# ospreyadc_secure register map
Vendor: Texas Instruments
Peripheral module from a debugger description file (folder CC35X1E).
Registers are 32-bit, read-write, reset 0x0 unless marked. A register's access mark holds for its fields unless they carry their own. Offsets are as the file gives them; lines under a group give offsets from that group; [hi:lo] are bit positions; {n}, {i} and the like mark numbered series; 'fields as' and 'values as' point back to an identical list; <NAME> marks a mode.

## ospreyadc_secure
0x00 adc_control0 reset 0x44554A — FUSE CONTROL 0 Primarily for lab testing, needs to be written by TI boot code All may not be used now, few spare are kept intentionally
  [31:0] TRIM0 — TRIM VALUE 0
0x04 adc_control1 reset 0x18F06630 — FUSE CONTROL 1 Primarily for lab testing, needs to be written by TI boot code All may not be used now, few spare are kept intentionally
  [31:0] TRIM1 — TRIM VALUE 1
0x08 adc_control2 reset 0x10208A — FUSE CONTROL 2 Primarily for lab testing, needs to be written by TI boot code All may not be used now, few spare are kept intentionally
  [31:0] TRIM2 — TRIM VALUE 2
0x0C adc_control3 — FUSE CONTROL 3 Primarily for lab testing, needs to be written by TI boot code All may not be used now, few spare are kept intentionally
  [15:0] TRIM3 — TRIM VALUE 3
0x10 refbuf reset 0xA6E09 — REFERENCE BUFFER
  [31:0] CFG — CONFIG bit[0] - Enable Internal Reference Mode bits[3:1] - Vsel for 3.3V mode Internal Reference Mode. Vrefbuf = 1.3V bits[6:4] - Vsel bits for higher tap points - For debug purpose <6:4> --> 001 (0.9V) <6:4> --> 010 (1.45V) <6:4> --> 100 (1.4V) bits[8:7] - Enable Test mux to check ground and reference thought test pins 01--> Vref Internal available to measure 10 --> vss Internal Reference available to measure bits[10:9] - Trim bits to change the bias current in Ref buf 1st stage bits[12:11] - Trim bits to change the bias current in Ref buf bits[14:13] - Trim bits to change the bias current in Ref buf output stage bits[16:15] - NU bits[19:17] - Vsel for 1.8V mode Internal Reference Mode .Vrefbuf = 1.35V bits[31:20] - NU
0x14 atb
  [7:0] CTRL — CONTROL bit0- master enable of test mux for AIP bit1- refbuf test enable bit2- 20uA current (scaled from PMCIO) test enable bit3- vbat_div test enable bit4- Tsense test enable bit5- Bandgap 0p9v test enable bit6- No connect bit7- No connect
0x1020 int_event0_iidx ro — INTERNAL EVENT 0 IRQ IDX This register provides the highest priority enabled interrupt index. 0x0 means no event pending. Interrupt 1 is the highest priority, 2 next highest, 4, 8, ... 2^31 is the least priority. That is, the least bit position that is set to 1 denotes the highest priority pending interrupt. The priority order is fixed. However, users can implement their own prioritization schemes using other registers that expose the full set of interrupts that have occurred. On each read, only one interrupt is indicated. On a read, the current interrupt (highest priority) is automatically cleared by the hardware and the corresponding interrupt flag in the RIS and MIS are cleared as well. After a read from the CPU (not from the debug interface), the register must be updated with the next highest priority interrupt, if none are pending, then it should display 0x0.
  [9:0] STAT — Interrupt index status
    0=NO_INTR (No bit is set means there is no pending interrupt request); 1=OVIFG (MEMRESx overflow interrupt); 7=UVIFG (MEMRESx underflow interrupt); 2=TOVIFG (Sequence Conversion time overflow interrupt); 3=HIGHIFG (High threshold compare interrupt); 4=LOWIFG (Low threshold compare interrupt); 5=INIFG (Primary Sequence In range comparator interrupt); {v}=MEMRESIFG{v-9} (MEMRES{v-9} data loaded interrupt) (v=9..32); 6=DMADONE (DMA done interrupt, generated on DMA transfer completion,)
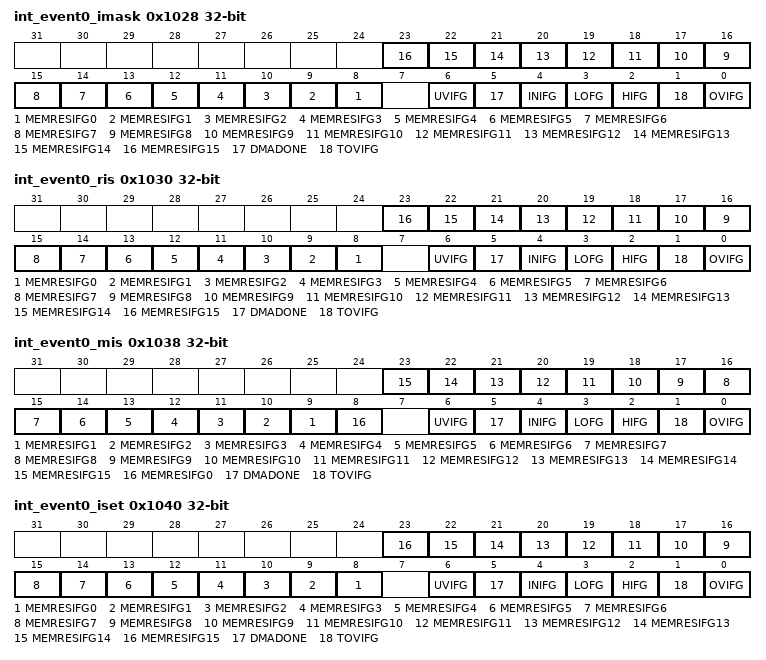
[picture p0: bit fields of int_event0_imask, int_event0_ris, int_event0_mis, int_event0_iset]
0x1028 int_event0_imask — INTERNAL EVENT 0 IRQ MASK Interrupt Mask. If a bit is set, then corresponding interrupt is un-masked. Un-masking the interrupt causes the raw interrupt to be visible in IIDX, as well as MIS.
  [n+8] MEMRESIFG{n} (n=0..15) — Raw interrupt status for MEMRES{n}. This bit is set to 1 when MEMRES{n} is loaded with a new conversion result. To clear this bit, corresponding bit in ICLR should be set to 1
    0=CLR (No new data ready.); 1=SET (A new data is ready to be read.)
  [6] UVIFG — Raw interrupt flag for MEMRESx underflow. This bit is reset to 0 by IIDX read or when corresponding bit in ICLR is set to 1.
    0=CLR (Interrupt is not pending.); 1=SET (Interrupt is pending.)
  [5] DMADONE — Raw interrupt flag for DMADONE. This bit is reset to 0 by IIDX read or when corresponding bit in ICLR_EX is set to 1.
    values as UVIFG
  [4] INIFG — Mask INIFG in MIS_EX register.
    values as UVIFG
  [3] LOFG — LOW FG Raw interrupt flag for the MEMRESx result register being below than the WCLOWx threshold of the window comparator. This bit is reset to 0 by IIDX read or when corresponding bit in ICLR_EX is set to 1.
    values as UVIFG
  [2] HIFG — Raw interrupt flag for the MEMRESx result register being higher than the WCHIGHx threshold of the window comparator. This bit is reset to 0 by IIDX read or when corresponding bit in ICLR_EX is set to 1.
    values as UVIFG
  [1] TOVIFG — Raw interrupt flag for sequence conversion timeout overflow. This bit is reset to 0 by IIDX read or when corresponding bit in ICLR_EX is set to 1.
    values as UVIFG
  [0] OVIFG — Raw interrupt flag for MEMRESx overflow. This bit is reset to 0 by IIDX read or when corresponding bit in ICLR_EX is set to 1.
    values as UVIFG
0x1030 int_event0_ris ro — INTERNAL EVENT 0 RAW IRQ STATUS Raw interrupt status. Reflects all pending interrupts, regardless of masking. The INT_EVENT0_RIS register allows the user to implement a poll scheme. A flag set in this register can be cleared by writing 1 to the ICLR register bit even if the corresponding IMASK bit is not enabled.
  [n+8] MEMRESIFG{n} (n=0..15) — Raw interrupt status for MEMRES{n}. This bit is set to 1 when MEMRES{n} is loaded with a new conversion result. To clear this bit, corresponding bit in ICLR should be set to 1
    values as int_event0_imask.MEMRESIFG0
  [6] UVIFG — Raw interrupt flag for MEMRESx underflow. This bit is reset to 0 by IIDX read or when corresponding bit in ICLR is set to 1.
    values as int_event0_imask.UVIFG
  [5] DMADONE — Raw interrupt flag for DMADONE. This bit is reset to 0 by IIDX read or when corresponding bit in ICLR_EX is set to 1.
    values as int_event0_imask.UVIFG
  [4] INIFG — Mask INIFG in MIS_EX register.
    values as int_event0_imask.UVIFG
  [3] LOFG — LOW FG Raw interrupt flag for the MEMRESx result register being below than the WCLOWx threshold of the window comparator. This bit is reset to 0 by IIDX read or when corresponding bit in ICLR_EX is set to 1.
    values as int_event0_imask.UVIFG
  [2] HIFG — HIGH FG Raw interrupt flag for the MEMRESx result register being higher than the WCHIGHx threshold of the window comparator. This bit is reset to 0 by IIDX read or when corresponding bit in ICLR_EX is set to 1.
    values as int_event0_imask.UVIFG
  [1] TOVIFG — Raw interrupt flag for sequence conversion timeout overflow. This bit is reset to 0 by IIDX read or when corresponding bit in ICLR_EX is set to 1.
    values as int_event0_imask.UVIFG
  [0] OVIFG — Raw interrupt flag for MEMRESx overflow. This bit is reset to 0 by IIDX read or when corresponding bit in ICLR_EX is set to 1.
    values as int_event0_imask.UVIFG
0x1038 int_event0_mis ro — INTERNAL EVENT 0 MASKED IRQ STATUS Masked interrupt status. This is an AND of the IMASK and RIS registers.
  [n+8] MEMRESIFG{n} (n=1..15) — Raw interrupt status for MEMRES{n}. This bit is set to 1 when MEMRES{n} is loaded with a new conversion result. To clear this bit, corresponding bit in ICLR should be set to 1
    values as int_event0_imask.MEMRESIFG0
  [8] MEMRESIFG0 — Raw interrupt status for MEMRES0. This bit is set to 1 when MEMRES0 is loaded with a new conversion result. To clear this bit, corresponding bit in ICLR should be set to 11
    values as int_event0_imask.MEMRESIFG0
  [6] UVIFG — Raw interrupt flag for MEMRESx underflow. This bit is reset to 0 by IIDX read or when corresponding bit in ICLR is set to 1.
    values as int_event0_imask.UVIFG
  [5] DMADONE — Raw interrupt flag for DMADONE. This bit is reset to 0 by IIDX read or when corresponding bit in ICLR_EX is set to 1.
    values as int_event0_imask.UVIFG
  [4] INIFG — Mask INIFG in MIS_EX register.
    values as int_event0_imask.UVIFG
  [3] LOFG — LOW FG Raw interrupt flag for the MEMRESx result register being below than the WCLOWx threshold of the window comparator. This bit is reset to 0 by IIDX read or when corresponding bit in ICLR_EX is set to 1.
    values as int_event0_imask.UVIFG
  [2] HIFG — HIGH FG Raw interrupt flag for the MEMRESx result register being higher than the WCHIGHx threshold of the window comparator. This bit is reset to 0 by IIDX read or when corresponding bit in ICLR_EX is set to 1.
    values as int_event0_imask.UVIFG
  [1] TOVIFG — Raw interrupt flag for sequence conversion timeout overflow. This bit is reset to 0 by IIDX read or when corresponding bit in ICLR_EX is set to 1.
    values as int_event0_imask.UVIFG
  [0] OVIFG — Raw interrupt flag for MEMRESx overflow. This bit is reset to 0 by IIDX read or when corresponding bit in ICLR_EX is set to 1.
    values as int_event0_imask.UVIFG
0x1040 int_event0_iset wo — INTERNAL EVENT 0 IRQ SET Interrupt set. Allows interrupts to be set by software (useful in diagnostics and safety checks). Writing a 1 to a bit in INT_EVENT0_ISET will set the event and therefore the related RIS bit also gets set. If the interrupt is enabled through the mask, then the corresponding MIS bit is also set.
  [n+8] MEMRESIFG{n} (n=0..15) — Raw interrupt status for MEMRES{n}. This bit is set to 1 when MEMRES{n} is loaded with a new conversion result. To clear this bit, corresponding bit in ICLR should be set to 1
    0=NO_EFFECT (No new data ready.); 1=SET (A new data is ready to be read.)
  [6] UVIFG — Raw interrupt flag for MEMRESx underflow. This bit is reset to 0 by IIDX read or when corresponding bit in ICLR_EX is set to 1.
    0=NO_EFFECT (Interrupt is not pending.); 1=SET (Interrupt is pending.)
  [5] DMADONE — Raw interrupt flag for DMADONE. This bit is reset to 0 by IIDX read or when corresponding bit in ICLR_EX is set to 1.
    values as UVIFG
  [4] INIFG — Mask INIFG in MIS_EX register.
    values as UVIFG
  [3] LOFG — LOW FG Raw interrupt flag for the MEMRESx result register being below than the WCLOWx threshold of the window comparator. This bit is reset to 0 by IIDX read or when corresponding bit in ICLR_EX is set to 1.
    values as UVIFG
  [2] HIFG — HIGH FG Raw interrupt flag for the MEMRESx result register being higher than the WCHIGHx threshold of the window comparator. This bit is reset to 0 by IIDX read or when corresponding bit in ICLR_EX is set to 1.
    values as UVIFG
  [1] TOVIFG — Raw interrupt flag for sequence conversion timeout overflow. This bit is reset to 0 by IIDX read or when corresponding bit in ICLR_EX is set to 1.
    values as UVIFG
  [0] OVIFG — Raw interrupt flag for MEMRESx overflow. This bit is reset to 0 by IIDX read or when corresponding bit in ICLR_EX is set to 1.
    values as UVIFG
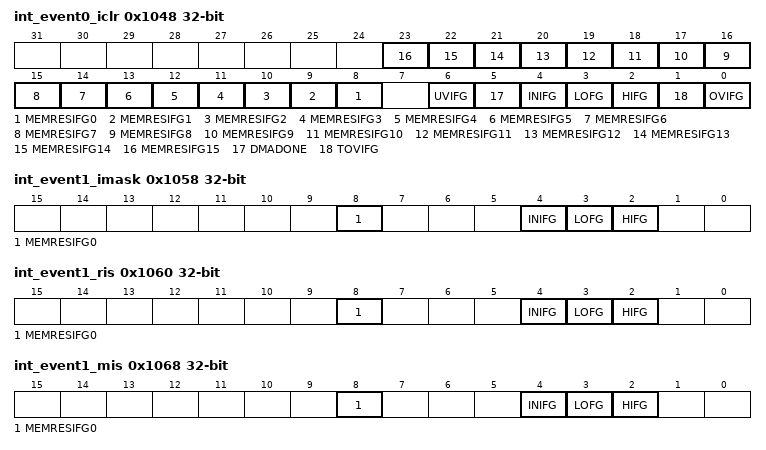
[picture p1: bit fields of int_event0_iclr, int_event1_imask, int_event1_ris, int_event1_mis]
0x1048 int_event0_iclr wo — INTERNAL EVENT 0 IRQ CLEAR Interrupt clear. Write a 1 to clear corresponding Interrupt.
  [n+8] MEMRESIFG{n} (n=0..15) — Raw interrupt status for MEMRES{n}. This bit is set to 1 when MEMRES{n} is loaded with a new conversion result. To clear this bit, corresponding bit in ICLR should be set to 1
    0=NO_EFFECT (No new data ready.); 1=CLR (A new data is ready to be read.)
  [6] UVIFG — Raw interrupt flag for MEMRESx underflow. This bit is reset to 0 by IIDX read or when corresponding bit in ICLR_EX is set to 1.
    0=NO_EFFECT (Interrupt is not pending.); 1=CLR (Interrupt is pending.)
  [5] DMADONE — Raw interrupt flag for DMADONE. This bit is reset to 0 by IIDX read or when corresponding bit in ICLR_EX is set to 1.
    values as UVIFG
  [4] INIFG — Mask INIFG in MIS_EX register.
    values as UVIFG
  [3] LOFG — LOW FG Raw interrupt flag for the MEMRESx result register being below than the WCLOWx threshold of the window comparator. This bit is reset to 0 by IIDX read or when corresponding bit in ICLR_EX is set to 1.
    values as UVIFG
  [2] HIFG — HIGH FG Raw interrupt flag for the MEMRESx result register being higher than the WCHIGHx threshold of the window comparator. This bit is reset to 0 by IIDX read or when corresponding bit in ICLR_EX is set to 1.
    values as UVIFG
  [1] TOVIFG — Raw interrupt flag for sequence conversion timeout overflow. This bit is reset to 0 by IIDX read or when corresponding bit in ICLR_EX is set to 1.
    values as UVIFG
  [0] OVIFG — Raw interrupt flag for MEMRESx overflow. This bit is reset to 0 by IIDX read or when corresponding bit in ICLR_EX is set to 1.
    values as UVIFG
0x1050 int_event1_iidx ro — INTERNAL EVENT 1 IRQ IDX This register provides the highest priority enabled interrupt index. 0x0 means no event pending. Interrupt 1 is the highest priority, 2 next highest, 4, 8, ... 2^31 is the least priority. That is, the least bit position that is set to 1 denotes the highest priority pending interrupt. The priority order is fixed. However, users can implement their own prioritization schemes using other registers that expose the full set of interrupts that have occurred. On each read, only one interrupt is indicated. On a read, the current interrupt (highest priority) is automatically cleared by the hardware and the corresponding interrupt flag in the RIS and MIS are cleared as well. After a read from the CPU (not from the debug interface), the register must be updated with the next highest priority interrupt, if none are pending, then it should display 0x0.
  [9:0] STAT — Interrupt index status
    0=NO_INTR (No bit is set means there is no pending interrupt request); 3=HIGHIFG (High threshold compare interrupt); 4=LOWIFG (Low threshold compare interrupt); 5=INIFG (Primary Sequence In range comparator interrupt); 9=MEMRESIFG0 (MEMRES0 data loaded interrupt)
0x1058 int_event1_imask — INTERNAL EVENT 1 IRQ MASK Interrupt Mask. If a bit is set, then corresponding interrupt is un-masked. Un-masking the interrupt causes the raw interrupt to be visible in IIDX, as well as MIS.
  [8] MEMRESIFG0 — Raw interrupt status for MEMRES0. This bit is set to 1 when MEMRES0 is loaded with a new conversion result. To clear this bit, corresponding bit in ICLR should be set to 1
    values as int_event0_imask.MEMRESIFG0
  [4] INIFG — Mask INIFG in MIS_EX register.
    values as int_event0_imask.UVIFG
  [3] LOFG — LOW FG Raw interrupt flag for the MEMRESx result register being below than the WCLOWx threshold of the window comparator. This bit is reset to 0 by IIDX read or when corresponding bit in ICLR_EX is set to 1.
    values as int_event0_imask.UVIFG
  [2] HIFG — HIGH FG Raw interrupt flag for the MEMRESx result register being higher than the WCHIGHx threshold of the window comparator. This bit is reset to 0 by IIDX read or when corresponding bit in ICLR_EX is set to 1.
    values as int_event0_imask.UVIFG
0x1060 int_event1_ris ro — INTERNAL EVENT 1 RAW IRQ STATUS Raw interrupt status. Reflects all pending interrupts, regardless of masking. The INT_EVENT1_RIS register allows the user to implement a poll scheme. A flag set in this register can be cleared by writing 1 to the ICLR register bit even if the corresponding IMASK bit is not enabled.
  fields as int_event1_imask
0x1068 int_event1_mis ro — INTERNAL EVENT 1 MASKED IRQ STATUS Masked interrupt status. This is an AND of the IMASK and RIS registers.
  fields as int_event1_imask
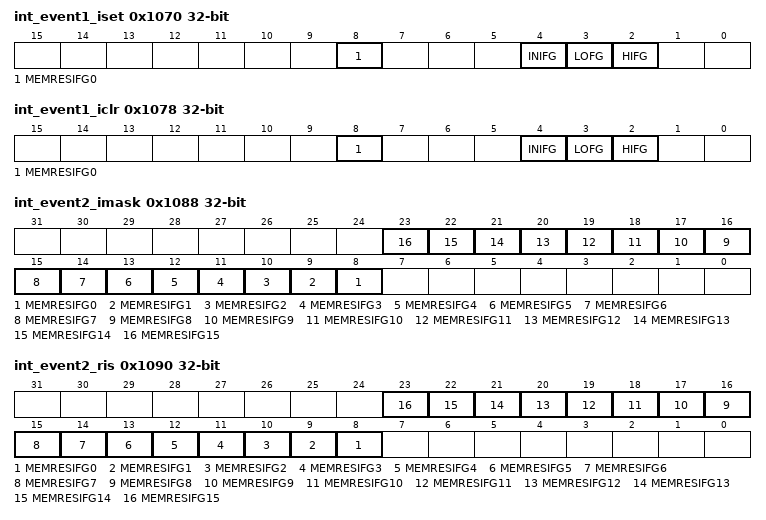
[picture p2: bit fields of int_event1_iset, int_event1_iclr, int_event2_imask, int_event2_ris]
0x1070 int_event1_iset wo — INTERNAL EVENT 1 IRQ SET Interrupt set. Allows interrupts to be set by software (useful in diagnostics and safety checks). Writing a 1 to a bit in INT_EVENT1_ISET will set the event and therefore the related RIS bit also gets set. If the interrupt is enabled through the mask, then the corresponding MIS bit is also set.
  [8] MEMRESIFG0 — Raw interrupt status for MEMRES0. This bit is set to 1 when MEMRES0 is loaded with a new conversion result. To clear this bit, corresponding bit in ICLR should be set to 1
    values as int_event0_iset.MEMRESIFG0
  [4] INIFG — Mask INIFG in MIS_EX register.
    values as int_event0_iset.UVIFG
  [3] LOFG — LOW FG Raw interrupt flag for the MEMRESx result register being below than the WCLOWx threshold of the window comparator. This bit is reset to 0 by IIDX read or when corresponding bit in ICLR_EX is set to 1.
    values as int_event0_iset.UVIFG
  [2] HIFG — HIGH FG Raw interrupt flag for the MEMRESx result register being higher than the WCHIGHx threshold of the window comparator. This bit is reset to 0 by IIDX read or when corresponding bit in ICLR_EX is set to 1.
    values as int_event0_iset.UVIFG
0x1078 int_event1_iclr wo — INTERNAL EVENT 1 IRQ CLEAR Interrupt clear. Write a 1 to clear corresponding Interrupt.
  [8] MEMRESIFG0 — Raw interrupt status for MEMRES0. This bit is set to 1 when MEMRES0 is loaded with a new conversion result. To clear this bit, corresponding bit in ICLR should be set to 1
    values as int_event0_iclr.MEMRESIFG0
  [4] INIFG — Mask INIFG in MIS_EX register.
    values as int_event0_iclr.UVIFG
  [3] LOFG — LOW FG Raw interrupt flag for the MEMRESx result register being below than the WCLOWx threshold of the window comparator. This bit is reset to 0 by IIDX read or when corresponding bit in ICLR_EX is set to 1.
    values as int_event0_iclr.UVIFG
  [2] HIFG — HIGH FG Raw interrupt flag for the MEMRESx result register being higher than the WCHIGHx threshold of the window comparator. This bit is reset to 0 by IIDX read or when corresponding bit in ICLR_EX is set to 1.
    values as int_event0_iclr.UVIFG
0x1080 int_event2_iidx ro — INTERNAL EVENT 2 IRQ IDX This register provides the highest priority enabled interrupt index. 0x0 means no event pending. Interrupt 1 is the highest priority, 2 next highest, 4, 8, ... 2^31 is the least priority. That is, the least bit position that is set to 1 denotes the highest priority pending interrupt. The priority order is fixed. However, users can implement their own prioritization schemes using other registers that expose the full set of interrupts that have occurred. On each read, only one interrupt is indicated. On a read, the current interrupt (highest priority) is automatically cleared by the hardware and the corresponding interrupt flag in the RIS and MIS are cleared as well. After a read from the CPU (not from the debug interface), the register must be updated with the next highest priority interrupt, if none are pending, then it should display 0x0.
  [9:0] STAT — Interrupt index status
    0=NO_INTR (No bit is set means there is no pending interrupt request); {v}=MEMRESIFG{v-9} (MEMRES{v-9} data loaded interrupt) (v=9..32)
0x1088 int_event2_imask — INTERNAL EVENT 2 IRQ MASK Interrupt Mask. If a bit is set, then corresponding interrupt is un-masked. Un-masking the interrupt causes the raw interrupt to be visible in IIDX, as well as MIS.
  [all] fields
    values as int_event0_imask.MEMRESIFG0
  [n+8] MEMRESIFG{n} (n=0..15) — Raw interrupt status for MEMRES{n}. This bit is set to 1 when MEMRES{n} is loaded with a new conversion result. To clear this bit, corresponding bit in ICLR should be set to 1
0x1090 int_event2_ris ro — INTERNAL EVENT 2 RAW IRQ STATUS Raw interrupt status. Reflects all pending interrupts, regardless of masking. The INT_EVENT2_RIS register allows the user to implement a poll scheme. A flag set in this register can be cleared by writing 1 to the ICLR register bit even if the corresponding IMASK bit is not enabled.
  fields as int_event2_imask
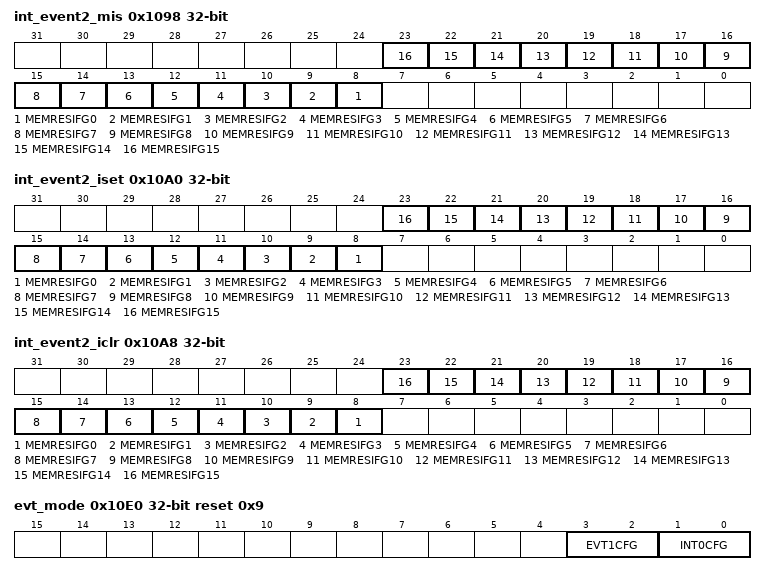
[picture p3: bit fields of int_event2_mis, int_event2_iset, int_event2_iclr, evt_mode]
0x1098 int_event2_mis ro — INTERNAL EVENT 2 MASKED IRQ STATUS Extension of Masked interrupt status. This is an AND of the IMASK and RIS registers.
  fields as int_event2_imask
0x10A0 int_event2_iset wo — INTERNAL EVENT 2 IRQ SET Interrupt set. Allows interrupts to be set by software (useful in diagnostics and safety checks). Writing a 1 to a bit in INT_EVENT2_ISET will set the event and therefore the related RIS bit also gets set. If the interrupt is enabled through the mask, then the corresponding MIS bit is also set.
  [all] fields
    values as int_event0_iset.MEMRESIFG0
  [n+8] MEMRESIFG{n} (n=0..15) — Raw interrupt status for MEMRES{n}. This bit is set to 1 when MEMRES{n} is loaded with a new conversion result. To clear this bit, corresponding bit in ICLR should be set to 1
0x10A8 int_event2_iclr wo — INTERNAL EVENT 2 IRQ CLEAR Interrupt clear. Write a 1 to clear corresponding Interrupt.
  [all] fields
    values as int_event0_iclr.MEMRESIFG0
  [n+8] MEMRESIFG{n} (n=0..15) — Raw interrupt status for MEMRES{n}. This bit is set to 1 when MEMRES{n} is loaded with a new conversion result. To clear this bit, corresponding bit in ICLR should be set to 1
0x10E0 evt_mode reset 0x9 — EVENT MODE Event mode register. It is used to select whether each line is disabled, in software mode (software clears the RIS) or in hardware mode (hardware clears the RIS)
  [3:2] EVT1CFG — EVENT 1 CONFIG Event line mode select for event corresponding to [IPSTANDARD.INT_EVENT1]
    0=DISABLE (The interrupt or event line is disabled.); 1=SOFTWARE (The interrupt or event line is in software mode. Software must clear the RIS.); 2=HARDWARE (The interrupt or event line is in hardware mode. The hardware (another module) clears automatically the associated RIS flag.)
  [1:0] INT0CFG — INTERNAL 0 CONFIG Event line mode select for event corresponding to [IPSTANDARD.INT_EVENT0]
    values as EVT1CFG
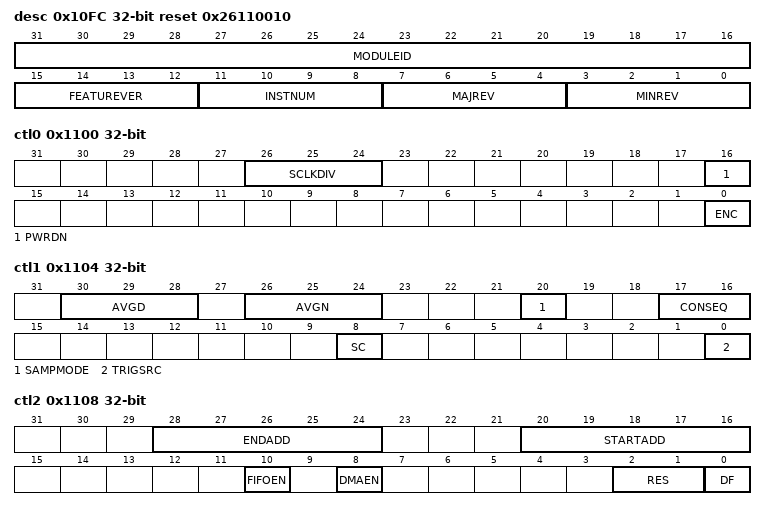
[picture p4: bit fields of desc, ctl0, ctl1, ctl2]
0x10FC desc ro reset 0x26110010 — This register identifies the peripheral and its exact version.
  [31:16] MODULEID — Module identification contains a unique peripheral identification number. The assignments are maintained in a central database for all of the platform modules to ensure uniqueness.
    0=MINIMUM (Smallest value); 0xFFFF=MAXIMUM (Highest possible value)
  [15:12] FEATUREVER — Feature Set for the module *instance*
    0=MINIMUM (Smallest value); 15=MAXIMUM (Highest possible value)
  [11:8] INSTNUM — Instance Number within the device. This will be a parameter to the RTL for modules that can have multiple instances
  [7:4] MAJREV — Major rev of the IP
    values as FEATUREVER
  [3:0] MINREV — Minor rev of the IP
    values as FEATUREVER
0x1100 ctl0 — ULP_ADCHP Control Register 0
  [26:24] SCLKDIV — NU - should keep as '0'. Selects divide ratio of of sample clock.
    0=DIV_BY_1 (Do not divide clock source); 1=DIV_BY_2 (Divide clock source by 2); 2=DIV_BY_4 (Divide clock source by 3); 3=DIV_BY_8 (Divide clock source by 4); 4=DIV_BY_16 (Divide clock source by 5); 5=DIV_BY_24 (Divide clock source by 6); 6=DIV_BY_32 (Divide clock source by 7); 7=DIV_BY_48 (Divide clock source by 8)
  [16] PWRDN — Auto or manual power down mode.
    0=AUTO (ADC is powered down on completion of a conversion, if there isn't a pending trigger.); 1=MANUAL (ADC is kept powered up as long as ADCEN bit is set.)
  [0] ENC — ULP_ADCHP Enable Conversions.
    0=OFF (ULP_ADCHP primary sequencer is off Transition from ON to OFF will abort the primary single or repeat sequence on a MEMCTLx boundary. (The current conversion will finish and result stored in corresponding MEMRESx)); 1=ON (ULP_ADCHP primary sequencer is ON. Waiting for valid trigger (Software or Hardware))
0x1104 ctl1 — Primary Sequence Control Register
  [30:28] AVGD — Hardware average denominator. The number to divide the accumulated value by (this is a shift). Note results register is maximum of 16-bits long so if not shifted appropriately result will be truncated.
    {v}=SHIFT{v} ({v} bit shift) (v=0..7)
  [26:24] AVGN — Hardware averager numerator. Selects number of conversions to accumulate for current MEMCTLx and then is get divided by AVGD. Result will be stored in MEMRESx.
    0=DISABLE (Disables averager.); 1=AVG_2 (Averages 2 conversions before storing in MEMRES register.); 2=AVG_4 (Averages 4 conversions before storing in MEMRES register.); 3=AVG_8 (Averages 8 conversions before storing in MEMRES register.); 4=AVG_16 (Averages 16 conversions before storing in MEMRES register.); 5=AVG_32 (Averages 32 conversions before storing in MEMRES register.); 6=AVG_64 (Averages 64 conversions before storing in MEMRES register.); 7=AVG_128 (Averages 128 conversions before storing in MEMRES register.)
  [20] SAMPMODE — ULP_ADCHP Primary Sequencer Sample Mode. This bit select the source of the sampling signal.
    0=AUTO (The sample timer high phase is used as sample signal.); 1=MANUAL (The external or software trigger is used as sample signal.)
  [17:16] CONSEQ — ULP_ADCHP Primary Sequencer Conversion Sequence Mode Select.
    0=SINGLE (The MEMCTLx pointed by PSTARTADD will be converted once.); 1=SEQUENCE (The primary sequence pointed by PSTARTADD will be converted once.); 2=REPEATSINGLE (The MEMCTLx pointed by PSTARTADD will be converted in repeat mode.); 3=REPEATSEQUENCE (Primary sequence pointed by PSTARTADD will be converted in repeat mode.)
  [8] SC — ULP_ADCHP Sequencer Start Of Conversion. If ULP_ADCHP is configured as FOLLOWER, this bit has no effect.
    1=START (When PSAMPMODE is set to MANUAL (1), setting this bit, will start the sampling phase. Sample phase will last as long as this bit is set. When PSAMPMODE is set to AUTO mode (0), setting this bit will trigger the timer based sample time.); 0=STOP (When PSAMPMODE is set to MANUAL (1) mode, clearing this bit will end the sampling phase and the conversion phase will start. When PSAMPMODE is set to AUTO mode (0), writing 0 has no effect. This bit is automatically cleared at the end of the current conversion.)
  [0] TRIGSRC — ULP_ADCHP Primary Sequence Trigger Source.
    0=SOFTWARE (Primary sequence or single conversion is triggered by software.); 1=EVENT (Primary sequence or single conversion is triggered by hardware event_0. (See device specific data-sheet for source for availability of this trigger))
0x1108 ctl2 — Primary Sequence Control Register
  [28:24] ENDADD — ULP_ADCHP Primary Sequence End Address. These bits select which MEMCTLx is the last MEMCTL for primary sequence mode. The value of PSTARTADD is 0x00 to 0x1F, corresponding to MEMRES0 to MEMRES31.
    {v}=ADDR_{v:02} (MEMCTL{v} is selected as end address of primary sequence.) (v=0..31)
  [20:16] STARTADD — ULP_ADCHP Primary Sequence Start Address. These bits select which MEMCTLx is used for single conversion or as first MEMCTL for primary sequence mode. The value of PSTARTADD is 0x00 to 0x1F, corresponding to MEMRES0 to MEMRES31.
    {v}=ADDR_{v:02} (MEMCTL{v} is selected as start address of a primary sequence or as a single conversion.) (v=0..31)
  [10] FIFOEN — Enables configuring of MEMRES register in FIFO mode.
    1=ENABLE (Enables FIFO mode of operation.); 0=DISABLE (Disabled FIFO mode of operation,)
  [8] DMAEN — Enable DMA for data transfer.
    0=DISABLE (DMA triggers are not enabled.); 1=ENABLE (Enable DMA.)
  [2:1] RES — ULP_ADCHP resolution. This bits define the conversion result resolution. Note : A value of 3 defaults to 12 bit resolution.
    0=BIT_12 (16-bits resolution)
  [0] DF — ULP_ADCHP data read-back format. Data is always stored in binary unsigned format.
    0=UNSIGNED (Digital result reads as Binary Unsigned.); 1=SIGNED (Digital result reads Signed Binary. (2s complement), left aligned.)
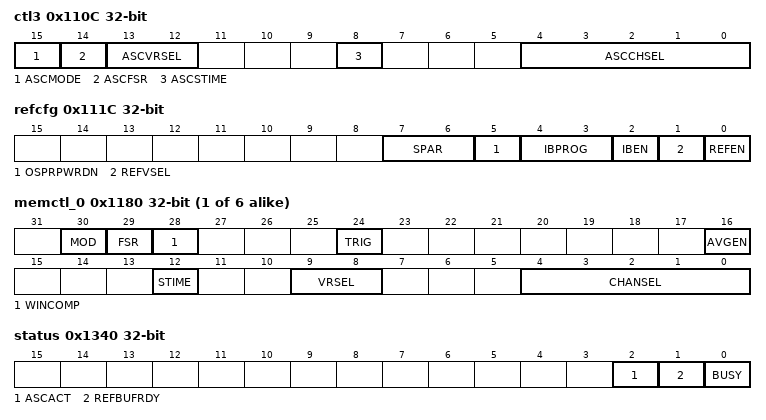
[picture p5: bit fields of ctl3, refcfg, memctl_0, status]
0x110C ctl3 — Control Register 3. This register is used to configure ADC for ad-hoc single conversion.
  [15] ASCMODE — Single vs Differential
  [14] ASCFSR — Full scale range of ADC limited to 1.8V or 3.3V *Exact range may be limited below the above mentioned voltages based on the design constraints
  [13:12] ASCVRSEL — Selects the voltage reference for ASC operation. VEREFM must be connected to on-board ground when external reference option is selected. Note: Writing value 0x3 defaults to INTREF.
    1=EXTREF (EXTREF pin reference.); 2=INTREF (Internal reference.)
  [8] ASCSTIME — ASC sample time compare value select. This is used to select between SCOMP0 and SCOMP1 registers for ASC operation.
    0=SEL_SCOMP0 (Select SCOMP0); 1=SEL_SCOMP1 (Select SCOMP1)
  [4:0] ASCCHSEL — ASC channel select
    {v}=CHAN_{v} (Selects channel {v}) (v=0..31)
0x1110 clkfreq — ADC sampling clock frequency range register.
  [2:0] FRANGE — Frequency Range. NU
    0=RANGE1TO4 (1 to 4 MHz); 1=RANGE4TO8 (4 to 8 MHz); 2=RANGE8TO16 (8 to 16 MHz); 3=RANGE16TO20 (16 to 20 MHz); 4=RANGE20TO24 (20 to 24 MHz); 5=RANGE24TO32 (24 to 32 MHz); 6=RANGE32TO40 (32 to 40 MHz); 7=RANGE40TO48 (40 to 48 MHz)
0x1114 scomp0 — ULP_ADCHP sample time register x Specifies the sample time, in number of ADCCLK cycles, when PSSM = 0 (AUTO) or SSSM = 0 (AUTO). CTL0.ENC must be set to 0 to write to this register.
  [13:0] SMP — SAMPLE This bit-field specify the number of sample time clocks (SCOMPx +1) for a conversion when SAMPLE_TIME in MEMCTLx is set to SCOMPx.
0x1118 scomp1 — ULP_ADCHP sample time register x Specifies the sample time, in number of ADCCLK cycles, when PSSM = 0 (AUTO) or SSSM = 0 (AUTO). CTL0.ENC must be set to 0 to write to this register.
  [13:0] SMP — SAMPLE This bitfield specify the number of sample time clocks (SCOMPx +1) for a conversion when SAMPLE_TIME in MEMCTLx is set to SCOMPx.
0x111C refcfg — REFBUF configuration register
  [7:6] SPAR — SPARE
  [5] OSPRPWRDN — OSPREY POWER DOWN Similar to ADC PWRDN control to save power in duty cycled mode of operation. 0 - AUTO, 1 - MANUAL In case of ADC, Sample time MMR needs to take into account time required to power on ADC. Since REF BUF may take time in us, recommendation is to use REFOKf th output oe buffer instead to start ADC conversion
  [4:3] IBPROG — Configures REFBUF IBIAS current output value
    0=1uA; 1=0.5uA; 2=2uA; 3=0.67uA
  [2] IBEN — REFBUF IBIAS enable
    0=DISABLE; 1=ENABLE
  [1] REFVSEL — Configures REFBUF output voltage
    0=V1P4 (REFBUF generates 1.4V output)
  [0] REFEN — REFBUF enable
    0=DISABLE; 1=ENABLE
0x1148 wclow — ULP_ADCHP Window Comparator Low Threshold 0 Register. The data format that is used to write and read WCLOW0 depends on the value of the DATAFORMAT bit in the CTL1 register. If DATAFORMAT = 0, the data is binary unsigned and right aligned. If DATAFORMAT = 1, the data is 2s complement and left aligned. Refer to the WCLOW0 bit-field description for details. CTL0.ENC must be set to 0 to write to this register. Design Note: To minimize cycles transforming data, the data written to WCLOW0 should be transformed into DATAFORMAT = 0 to match the MEMRESx register so a direct comparison can be done. Thus, there are extra cycles to write to this register but no penalty when a comparison is done.
  [15:0] DATA — Low threshold register 0. If DATAFORMAT = 0, unsigned binary format has to be used: The value based on the resolution has to be right aligned with the MSB on the left. For 14-bits and 12-bits resolution, unused bit have to be 0s Reset value is 0x0000. If DATAFORMAT = 1, 2s-complement format has to be used. The value based on the resolution has to be left aligned with the LSB on the right. For 14-bits and 12-bits resolution, unused bit have to be 0s Reset value is 0x8000.
0x1150 wchigh — WC HIGH ULP_ADCHP Window Comparator High Threshold 0 Register. The data format that is used to write and read WCHIGH0 depends on the value of the DATAFORMAT bit in the CTL1 register. If DATAFORMAT = 0, the data is binary unsigned and right aligned. If DATAFORMAT = 1, the data is 2s complement and left aligned. Refer to the WCHIGH0 bit-field description for details. CTL0.ENC must be set to 0 to write to this register. Design Note: To minimize cycles transforming data, the data written to WCHIGH0 should be transformed in DATAFORMAT = 0 to match the MEMRESx register so a direct comparison can be done. Thus, there are extra cycles to write to this register but no penalty when a comparison is done.
  [15:0] DATA — ULP_ADCHP Low threshold register 0. If DATAFORMAT = 0, unsigned binary format has to be used: The threshold value has to be right aligned, with the MSB on the left. Reset value are: 0xFFFF (16-bit), 0x3FFF (14-bit) or 0x0FFF (12-bit) If DATAFORMAT = 1, 2s-complement format has to be used. The value based on the resolution has to be left aligned with the LSB on the right. For 14-bits and 12-bits resolution, unused bit have to be 0s Reset value are: 0x7FFF (16-bit), 0x7FFC (14-bit) or 0x7FF0 (12-bit)
0x1160 fifodata ro — Virtual data register used to do a read from FIFO.
  [31:0] DATA — Read from data field returns the data from the top of FIFO.
0x1170 ascres ro — ASC result register.
  [15:0] DATA
{0x1180+4i} memctl_{i} reset not defined (i=0..5) — ULP_ADCHP Conversion Memory Control Register x (x=0 to 31) CTL0.ENC must be set to 0 to write to this register.
  [30] MOD — MODE Single vs Differential
  [29] FSR — Full scale range of ADC limited to 1.8V or 3.3V '0' - 3.3V '1' - 1.8V * Exact range may be limited below the above mentioned voltages based on the design constraints
  [28] WINCOMP — Window Comparator Enable. Select for the current conversion if the Window Comparator feature is used.
    0=DISABLE (Window Comparator is disabled.); 1=ENABLE (Window Comparator is enabled.)
  [24] TRIG — TRIG. Indicates if a trigger will be needed to step to the next MEMCTL in the sequence.
    0=AUTO_NEXT (Automatically step to next MEMCTL register.); 1=TRIGGER_NEXT (A valid trigger will step to next MEMCTL register.)
  [16] AVGEN — Enable averaging.
    0=DISABLE (Averaging disabled.); 1=ENABLE (Averaging enabled.)
  [12] STIME — Selects the source of sample timer period. Can choose between SCOMP0 and SCOMP1.
    0=SEL_SCOMP0 (Select SCOMP0.); 1=SEL_SCOMP1 (Select SCOMP1.)
  [9:8] VRSEL — Selects the combination of V(Rp) and V(Rn) sources. It is recommended to connect VeREFn0 to on-board ground when VeREFn is selected for V(Rn). Note: A value of 3 defaults to INTREF and value of 0 defaults to EXTREF.
    1=EXTREF (EXTREF pin reference.); 2=INTREF (INTREF reference.)
  [4:0] CHANSEL — ULP_ADCHP Input channel select. In single ended mode, any of the 32 channels can be selected. In differential mode, this field will select which EVEN channel to be connected to the vin+ input. The vin- is automatically set to the next ODD channel. (CHANSEL+1)
    0=CHAN_0 (If DIFIN= 0: Ain+ = A0. If DIFIN = 1: Ain+ = A0, Ain- = A1); 1=CHAN_1 (If DIFIN= 0: Ain+ = A1. If DIFIN = 1: Ain+ = A0, Ain- = A1); 2=CHAN_2 (If DIFIN = 0: Ain+ = A2. If DIFIN = 1: Ain+ = A2, Ain- = A3); 3=CHAN_3 (If DIFIN = 0: Ain+ = A3. If DIFIN = 1: Ain+ = A2, Ain- = A3); 4=CHAN_4 (If DIFIN = 0: Ain+ = A4. If DIFIN = 1: Ain+ = A4, Ain- = A5); 5=CHAN_5 (If DIFIN = 0: Ain+ = A5. If DIFIN = 1: Ain+ = A4, Ain- = A5); 6=CHAN_6 (If DIFIN = 0: Ain+ = A6. If DIFIN = 1: Ain+ = A6, Ain- = A7); 7=CHAN_7 (If DIFIN = 0: Ain+ = A7. If DIFIN = 1: Ain+ = A6, Ain- = A7); 8=CHAN_8 (If DIFIN = 0: Ain+ = A8. If DIFIN = 1: Ain+ = A8, Ain- = A9); 9=CHAN_9 (If DIFIN= 0: Ain+ = A9. If DIFIN = 1: Ain+ = A8, Ain- = A9); 10=CHAN_10 (If DIFIN= 0: Ain+ = A10. If DIFIN = 1: Ain+ = A10, Ain- = A11); 11=CHAN_11 (If DIFIN= 0: Ain+ = A11. If DIFIN = 1: Ain+ = A10, Ain- = A11); 12=CHAN_12 (If DIFIN= 0: Ain+ = A12. If DIFIN = 1: Ain+ = A12, Ain- = A13); 13=CHAN_13 (If DIFIN= 0: Ain+ = A13. If DIFIN = 1: Ain+ = A12, Ain- = A13); 14=CHAN_14 (If DIFIN= 0: Ain+ = A14. If DIFIN = 1: Ain+ = A14, Ain- = A15); 15=CHAN_15 (If DIFIN= 0: Ain+ = A15. If DIFIN = 1: Ain+ = A14, Ain- = A15); 16=CHAN_16 (If DIFIN= 0: Ain+ = A16. If DIFIN = 1: Ain+ = A16, Ain- = A17); 17=CHAN_17 (If DIFIN= 0: Ain+ = A17. If DIFIN = 1: Ain+ = A16, Ain- = A17); 18=CHAN_18 (If DIFIN= 0: Ain+ = A18. If DIFIN = 1: Ain+ = A18, Ain- = A19); 19=CHAN_19 (If DIFIN= 0: Ain+ = A19. If DIFIN = 1: Ain+ = A18, Ain- = A19); 20=CHAN_20 (If DIFIN= 0: Ain+ = A20. If DIFIN = 1: Ain+ = A20, Ain- = A21); 21=CHAN_21 (If DIFIN= 0: Ain+ = A21. If DIFIN = 1: Ain+ = A20, Ain- = A21); 22=CHAN_22 (If DIFIN= 0: Ain+ = A22. If DIFIN = 1: Ain+ = A22, Ain- = A23); 23=CHAN_23 (If DIFIN= 0: Ain+ = A23. If DIFIN = 1: Ain+ = A22, Ain- = A23); 24=CHAN_24 (If DIFIN= 0: Ain+ = A24. If DIFIN = 1: Ain+ = A24, Ain- = A25); 25=CHAN_25 (If DIFIN= 0: Ain+ = A25. If DIFIN = 1: Ain+ = A24, Ain- = A25); 26=CHAN_26 (If DIFIN= 0: Ain+ = A26. If DIFIN = 1: Ain+ = A26, Ain- = A27); 27=CHAN_27 (If DIFIN= 0: Ain+ = A27. If DIFIN = 1: Ain+ = A26, Ain- = A27); 28=CHAN_28 (If DIFIN= 0: Ain+ = A28. If DIFIN = 1: Ain+ = A28, Ain- = A29); 29=CHAN_29 (If DIFIN= 0: Ain+ = A29. If DIFIN = 1: Ain+ = A28, Ain- = A29); 30=CHAN_30 (If DIFIN= 0: Ain+ = A30. If DIFIN = 1: Ain+ = A30, Ain- = A31); 31=CHAN_31 (If DIFIN= 0: Ain+ = A31. If DIFIN = 1: Ain+ = A30, Ain- = A31)
{0x1280+4i} memres_{i} ro (i=0..15) — Memory Results Register
  [15:0] DATA — MEMRESx result register. If DATAFORMAT = 0, unsigned binary: The conversion results are right aligned. In 14 and 12 bit mode, the unused MSB bits are forced to 0. If DATAFORMAT = 1, 2s-complement format: The conversion results are left aligned. In 14 and 12 bit mode, the unused LSB bits are forced to 0. The data is stored in the right-justified format and is converted to the left-justified 2s-complement format during read back. Reading this register clears the corresponding bit in RIS.
0x1340 status ro — STATUS ULP_ADCHP Status Register 0
  [2] ASCACT — ASC active
    1=ACTIVE (ASC active); 0=IDLE (Idle or done)
  [1] REFBUFRDY — Indicates reference buffer is powered up.
    1=READY (REFBUF is ready.); 0=NOTREADY (REFBUF not ready.)
  [0] BUSY — ULP_ADCHP busy. This bit indicates that an active sample or conversion operation is in progress.
    1=ACTIVE (A sample or conversion is in progress.); 0=IDLE (No sampling or conversion in progress.)
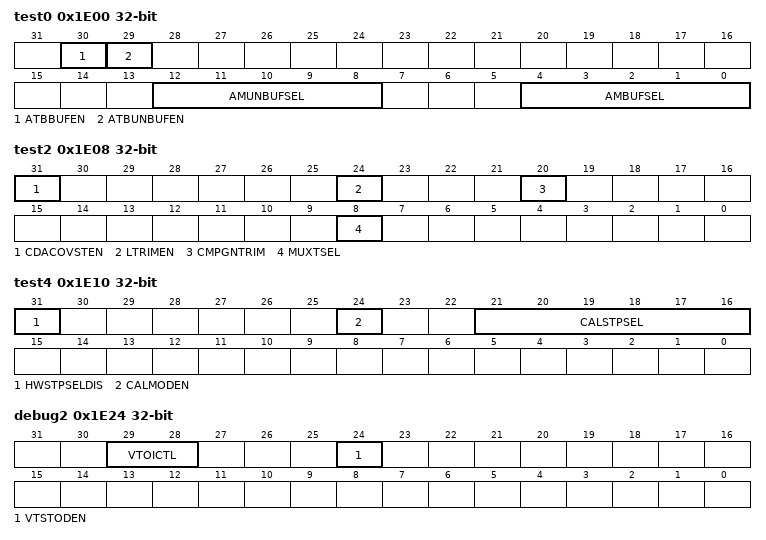
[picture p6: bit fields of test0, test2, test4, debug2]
0x1E00 test0 — Test0 register for ATB Mux sel for ATBBUF and ATBUNBUF
  [30] ATBBUFEN — ATB_BUF Enable ADC Signal = ull_dft_atb_usc_ulpadchp_en<1> := 1
  [29] ATBUNBUFEN — ATB_UNBUF Enable ADC Signal = ull_dft_atb_usc_ulpadchp_en<0> := 1
  [12:8] AMUNBUFSEL — ATBUNBUF MUX Sel ull_dft_atb_usc_ulpadchp_unbuf_muxsel<4> : Vint REF BUF1 Output ull_dft_atb_usc_ulpadchp_unbuf_muxsel<3> : Vint REF BUF2 Output ull_dft_atb_usc_ulpadchp_unbuf_muxsel<2> : ADC internal VREFN signal ull_dft_atb_usc_ulpadchp_unbuf_muxsel<1> : Not used ull_dft_atb_usc_ulpadchp_unbuf_muxsel<0> : Not used
  [4:0] AMBUFSEL — ATBBUF MUX Sel Bit 4: DIG LDO Output Bit 3: Ana LDO output Bit 2: CM buffer output Bit 1 , and Bit 0 : VDDA3P3 signal
0x1E04 test1 — DTB MUX Selection
  [4:0] DTBMSEL — DTB Mux Sel ull_dft_dtb_usc_ulpadchp_muxsel<0x0> : ADC 16 bit data ull_dft_dtb_usc_ulpadchp_muxsel<0x1> : DTB0: ADC CLK DIV2 DTB1 - 9 : See implementation document for detail signal name.
0x1E08 test2 — ATB Ch sel as ADC input MUX Test mode sel, ATB REF and CAP OSVT enable
  [31] CDACOVSTEN — ADC P_CDAC CAP OVST Enable Control Signal ull_usc_ulpadchp_dft_i<31>:1 -> ADC CDAC CAP OVST Enable Control Signal
  [24] LTRIMEN — Latch trim enable.
  [20] CMPGNTRIM — COMP GAIN TRIM Resistor Trim Enable Control Signal ull_usc_ulpadchp_dft_i<30>:1 -> Resistor Trim Enable Control Signal
  [8] MUXTSEL — MUX TEST SELECTOR ADC Input MUX test mode selection: ull_usc_ulpachp_mux_testmode_i<1:0>: 0x01 : Selected Even ch short with ATBBUF CH sel ull_usc_ulpachp_mux_testmode_i<1:0>: 0x10 : Selected Odd ch short with ATBUnBUFCh sel
0x1E0C test3 — ADC CAL Accumulation Register
  [31:0] CALACUML — Accumulation of # samples during Calibration step
0x1E10 test4 — CAL Control register: Average Sample count, Step number, Recall En and Debug option to override ull_usc_ulpadchp_dft_i<26:0>.
  [31] HWSTPSELDIS — By Enabling this bit, DLC written value overwritten of ull_usc_ulpadchp_dft_i<26:0> from TEST7 register. This is for debug.
  [24] CALMODEN — ADC CDAC Calibration mode enable
  [21:16] CALSTPSEL — ADC CAL STEP SELECTION
0x1E14 test5 — This register updated ull_usc_ulpadchp_dft_i[26:0] value if Test 5: HW_STEP_SEL_DIS bit enable
  [9:0] CALCAPCTL — This register updated ull_usc_ulpadchp_dft_i[26:0] value if Test 5: HW_STEP_SEL_DIS bit enabled ull_usc_ulpadchp_dft_i[26:0]
0x1E18 test6 — REFBUF ATB selection. This register is used to select the REFBUF signals on ATB.
  [3:0] ATBSEL — ATB selection. The undefined values are reserved and should not be used.
    0=Both ATEST0 and ATEST1 switches are open; 1=REFBUF output (ATEST0/BUF path); 2=1st stage output (ATEST0/BUF path); 4=Resistor ladder feedback (ATEST0/BUF path); 8=1st stage source (ATEST1/UNBUF path)
0x1E20 debug1 reset 0x801000 — DEBUG1 COMP CTL Debug register
  [31:0] CTRL — COMP Debug signals control ull_usc_ulpadchp_ctrl_comp_i[31]: Enable the use of external value for comaparor gain and IB settings
0x1E24 debug2 — DEBUG 2 OSC, LATCH_OS, VTOI Debug CTL register
  [29:28] VTOICTL — VTOI Debug Signals control ull_usc_ulpadchp_ctrl_vtoi_i[3:0]
  [24] VTSTODEN — VTOI TETSMODE Enable
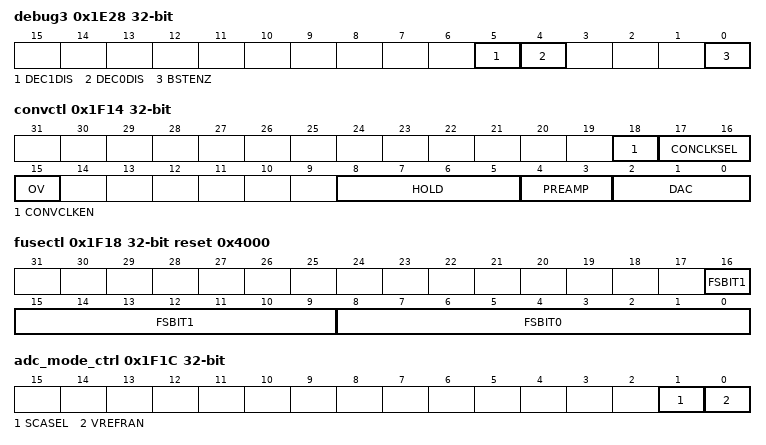
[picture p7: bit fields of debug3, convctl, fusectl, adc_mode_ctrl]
0x1E28 debug3 — DEBUG 3 Boost, DCLK Sel, Int coex dirty and Dec disable debug control register
  [5] DEC1DIS — DEC1 Disable control signal
  [4] DEC0DIS — DEC0 Disable control signal
  [0] BSTENZ — BOOST ENZ
0x1E2C debug4 — DEBUG 4 ADC MSIP Control signal for Debug: adc_ctrl<31:0>
  [15:0] ADCCTL0 — ADC CONTROL 0 ADC MSIP Control signal for Debug: adc_ctrl<15:0>
0x1F14 convctl — Conversion Control
  [18] CONVCLKEN — CONV CLK ICG EN should be enabled after selecting CONV CLK
  [17:16] CONCLKSEL — CONVERSION CLOCK SELECTOR ADC functional clock selection 0x0 - (Reset/Default) CLK_GATE 0x1 - SOC_CLK 0x2 - HFXT 0x3 - SOC_PLL_CLK_DIV note: not glitch free, therefore ICG should be enabled after selecting the right clk
  [15] OV — OVERRIDE 1 : Override, 0 : Use LUT values LUT is mentioned since the proposal was to pick up values automatically based on Internal vs External reference
  [8:5] HOLD — 000 : 1 Clock delay, ...., 111 : 8 Clock delay bit[3] - don't care and not used
  [4:3] PREAMP — 00 : 1 Clock delay, ..., 11 : 4 Clock delay
  [2:0] DAC — 000 : 1 Clock delay, ...., 111 : 8 Clock delay
0x1F18 fusectl reset 0x4000
  [16:9] FSBIT1 — FUSE BITS 1 values for fuse OV
  [8:0] FSBIT0 — FUSE BITS 0 values for fuse OV
0x1F1C adc_mode_ctrl — MODE CONTROL
  [1] SCASEL — SCALE SELECT 0 --> Normal output 1 --> scale 0-4223 in 0-4095 (efectively supporting 0-3.3V in 12 bit space)
  [0] VREFRAN — VOLTAGE REFERENCE RANGE 0 --> 0 - 4095 in 0 - 3.2V 1 --> 0 - 4095 in 0.1 to 3.3V Only in Single Ended mode
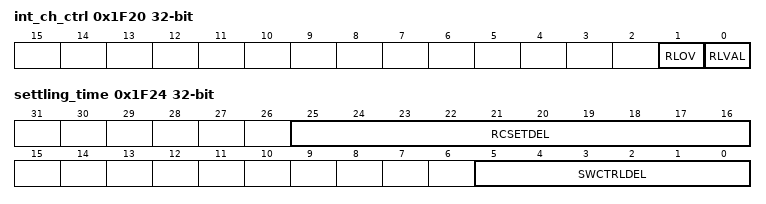
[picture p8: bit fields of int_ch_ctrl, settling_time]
0x1F20 int_ch_ctrl — INTERNAL CHANNEL CONTROL
  [1] RLOV — RLADDER OVERRIDE Override Enable/Disable control for R-ladder inside RFCIO. This provides divided voltage to ADC by limiting the max. voltage. Default : 0 use value driven by ADC FSM
  [0] RLVAL — RLADDER VALUE 0 --> 0 - 4095 in 0 - 3.2V 1 --> 0 - 4095 in 0.1 to 3.3V Only in Single Ended mode
0x1F24 settling_time reset not defined
  [25:16] RCSETDEL — RC SETTLING DELAY delay value for RC SETTLING DELAY. value should be added to switch control delay. calculated using conv clk '1' - 1 conv clks '2' - 2 conv clks ... '3FF' - 1023 conv clks
  [5:0] SWCTRLDEL — SWITCH CONTROL DELAY delay value for SWITCH CONTROL. calculated using conv clk '1' - 2 conv clks '2' - 3 conv clks ... '3F' - 64 conv clks
0x2000 clk_en — ADC CLK CONFIG
  [0] EN — ENABLE enables system clk to work with ADC '1' - enable adc clk '0' - disable adc clk
